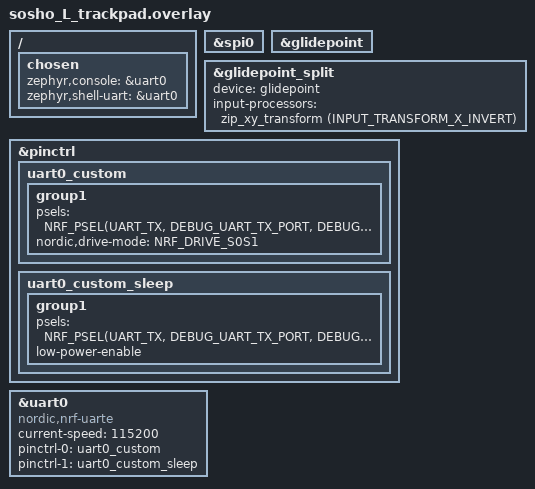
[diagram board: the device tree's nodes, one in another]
#include "sosho_L.dtsi"
#include <input/processors.dtsi>
#include <dt-bindings/zmk/input_transform.h>
#define DEBUG_UART_TX_PORT 1
#define DEBUG_UART_TX_PIN  12

&spi0 {
    status = "okay";
};

&glidepoint {
    status = "okay";
    /* invert-x; */
};

&glidepoint_split {
    status = "okay";
    device = <&glidepoint>;

    input-processors =
        <&zip_xy_transform (INPUT_TRANSFORM_X_INVERT)>;
};


/ {
    chosen {
        zephyr,console = &uart0;
        zephyr,shell-uart = &uart0;
    };
};

&pinctrl {
    uart0_custom: uart0_custom {
        group1 {
            psels = <NRF_PSEL(UART_TX, DEBUG_UART_TX_PORT, DEBUG_UART_TX_PIN)>;
            nordic,drive-mode = <NRF_DRIVE_S0S1>;
        };
    };

    uart0_custom_sleep: uart0_custom_sleep {
        group1 {
            psels = <NRF_PSEL(UART_TX, DEBUG_UART_TX_PORT, DEBUG_UART_TX_PIN)>;
            low-power-enable;
        };
    };
};

&uart0 {
    compatible = "nordic,nrf-uarte";
    status = "okay";
    current-speed = <115200>;
    pinctrl-0 = <&uart0_custom>;
    pinctrl-1 = <&uart0_custom_sleep>;
    pinctrl-names = "default", "sleep";
};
